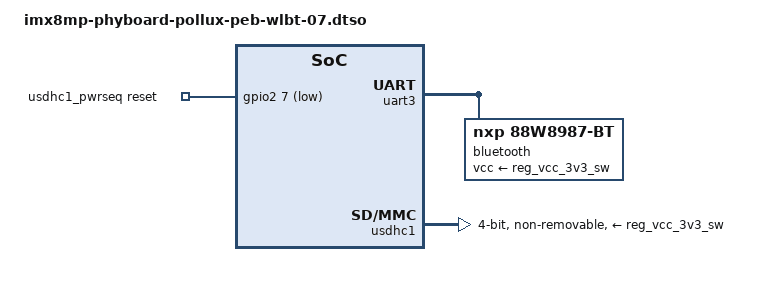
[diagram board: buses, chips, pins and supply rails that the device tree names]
// SPDX-License-Identifier: GPL-2.0-or-later OR MIT
/*
* Copyright (C) 2026 PHYTEC Messtechnik GmbH
*/

#include <dt-bindings/clock/imx8mp-clock.h>
#include <dt-bindings/gpio/gpio.h>
#include <dt-bindings/interrupt-controller/irq.h>
#include "imx8mp-pinfunc.h"

/dts-v1/;
/plugin/;

&{/} {
	usdhc1_pwrseq: pwr-seq {
		compatible = "mmc-pwrseq-simple";
		reset-gpios = <&gpio2 7 GPIO_ACTIVE_LOW>;
	};
};

&iomuxc {
	pinctrl_uart3: uart3grp {
		fsl,pins = <
			MX8MP_IOMUXC_SD1_RESET_B__UART3_DCE_RTS	0x140 /* RTS */
			MX8MP_IOMUXC_SD1_STROBE__UART3_DCE_CTS	0x140 /* CTS */
			MX8MP_IOMUXC_UART3_RXD__UART3_DCE_RX	0x140 /* RX */
			MX8MP_IOMUXC_UART3_TXD__UART3_DCE_TX	0x140 /* TX */
		>;
	};

	pinctrl_usdhc1: usdhc1grp {
		fsl,pins = <
			MX8MP_IOMUXC_SD1_CLK__USDHC1_CLK	0x190 /* SDIO_CLK */
			MX8MP_IOMUXC_SD1_CMD__USDHC1_CMD	0x1d0 /* SDIO_CMD */
			MX8MP_IOMUXC_SD1_DATA0__USDHC1_DATA0	0x1d0 /* SDIO_D0 */
			MX8MP_IOMUXC_SD1_DATA1__USDHC1_DATA1	0x1d0 /* SDIO_D1 */
			MX8MP_IOMUXC_SD1_DATA2__USDHC1_DATA2	0x1d0 /* SDIO_D2 */
			MX8MP_IOMUXC_SD1_DATA3__USDHC1_DATA3	0x1d0 /* SDIO_D3 */
		>;
	};

	pinctrl_wlbt: wlbtgrp {
		fsl,pins = <
			MX8MP_IOMUXC_SPDIF_EXT_CLK__GPIO5_IO05	0x106 /* WAKE_DEV */
			MX8MP_IOMUXC_SD1_DATA5__GPIO2_IO07	0x106 /* PDn */
			MX8MP_IOMUXC_SD1_DATA7__GPIO2_IO09	0x106 /* WAKE_HOST */
		>;
	};
};

&uart3 {
	assigned-clocks = <&clk IMX8MP_CLK_UART3>;
	assigned-clock-parents = <&clk IMX8MP_SYS_PLL1_80M>;
	pinctrl-0 = <&pinctrl_uart3>;
	pinctrl-names = "default";
	uart-has-rtscts;
	status = "okay";

	bluetooth {
		compatible = "nxp,88w8987-bt";
		vcc-supply = <&reg_vcc_3v3_sw>;
	};
};

&usdhc1 {
	bus-width = <4>;
	keep-power-in-suspend;
	max-frequency = <50000000>;
	mmc-pwrseq = <&usdhc1_pwrseq>;
	non-removable;
	pinctrl-0 = <&pinctrl_usdhc1>, <&pinctrl_wlbt>;
	pinctrl-names = "default";
	vmmc-supply = <&reg_vcc_3v3_sw>;
	wakeup-source;
	status = "okay";
};
